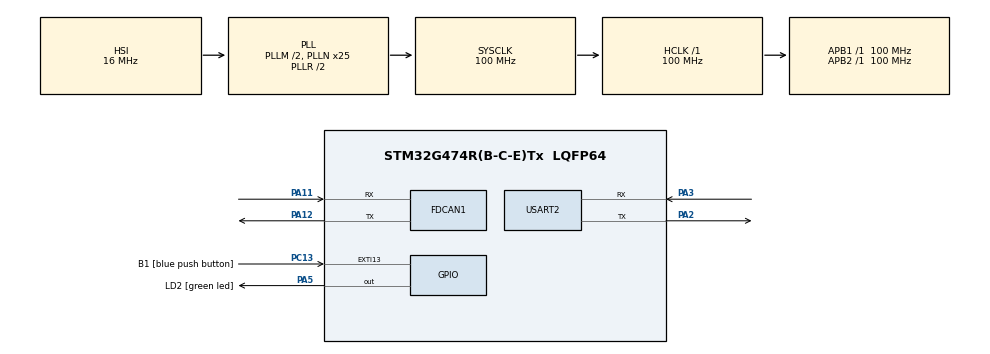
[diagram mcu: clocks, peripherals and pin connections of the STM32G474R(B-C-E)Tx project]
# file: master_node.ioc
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CRC.CRCLength=CRC_POLYLENGTH_16B
CRC.DefaultInitValueUse=DEFAULT_INIT_VALUE_DISABLE
CRC.DefaultPolynomialUse=DEFAULT_POLYNOMIAL_DISABLE
CRC.GeneratingPolynomial=X12+X5+X0
CRC.InitValue=0xFFFF
Dma.Request0=USART2_RX
Dma.Request1=USART2_TX
Dma.USART2_RX.0.Direction=DMA_PERIPH_TO_MEMORY
Dma.USART2_RX.0.EventEnable=DISABLE
Dma.USART2_RX.0.Instance=DMA1_Channel1
Dma.USART2_RX.0.MemDataAlignment=DMA_MDATAALIGN_BYTE
Dma.USART2_RX.0.MemInc=DMA_MINC_ENABLE
Dma.USART2_RX.0.Mode=DMA_NORMAL
Dma.USART2_RX.0.PeriphDataAlignment=DMA_PDATAALIGN_BYTE
Dma.USART2_RX.0.PeriphInc=DMA_PINC_DISABLE
Dma.USART2_RX.0.Polarity=HAL_DMAMUX_REQ_GEN_RISING
Dma.USART2_RX.0.Priority=DMA_PRIORITY_LOW
Dma.USART2_RX.0.RequestNumber=1
Dma.USART2_RX.0.SignalID=NONE
Dma.USART2_RX.0.SyncEnable=DISABLE
Dma.USART2_RX.0.SyncPolarity=HAL_DMAMUX_SYNC_NO_EVENT
Dma.USART2_RX.0.SyncRequestNumber=1
Dma.USART2_RX.0.SyncSignalID=NONE
Dma.USART2_TX.1.Direction=DMA_MEMORY_TO_PERIPH
Dma.USART2_TX.1.EventEnable=DISABLE
Dma.USART2_TX.1.Instance=DMA1_Channel2
Dma.USART2_TX.1.MemDataAlignment=DMA_MDATAALIGN_BYTE
Dma.USART2_TX.1.MemInc=DMA_MINC_ENABLE
Dma.USART2_TX.1.Mode=DMA_NORMAL
Dma.USART2_TX.1.PeriphDataAlignment=DMA_PDATAALIGN_BYTE
Dma.USART2_TX.1.PeriphInc=DMA_PINC_DISABLE
Dma.USART2_TX.1.Polarity=HAL_DMAMUX_REQ_GEN_RISING
Dma.USART2_TX.1.Priority=DMA_PRIORITY_LOW
Dma.USART2_TX.1.RequestNumber=1
Dma.USART2_TX.1.SignalID=NONE
Dma.USART2_TX.1.SyncEnable=DISABLE
Dma.USART2_TX.1.SyncPolarity=HAL_DMAMUX_SYNC_NO_EVENT
Dma.USART2_TX.1.SyncRequestNumber=1
Dma.USART2_TX.1.SyncSignalID=NONE
FDCAN1.CalculateBaudRateNominal=1000000
FDCAN1.CalculateTimeBitNominal=1000
FDCAN1.CalculateTimeQuantumNominal=50.0
FDCAN1.NominalPrescaler=5
FDCAN1.NominalTimeSeg1=13
FDCAN1.NominalTimeSeg2=6
FREERTOS.Tasks01=defaultTask,8,128,defaultTaskFunc,Default,NULL,Dynamic,NULL,NULL
FREERTOS.configTOTAL_HEAP_SIZE=8192
Mcu.Family=STM32G4
Mcu.Name=STM32G474R(B-C-E)Tx
Mcu.Package=LQFP64
NVIC.DMA1_Channel1_IRQn=true\:5\:0\:false\:true\:true\:1\:true\:false\:true\:true
NVIC.DMA1_Channel2_IRQn=true\:5\:0\:false\:false\:true\:true\:false\:true\:true
NVIC.EXTI15_10_IRQn=true\:5\:0\:false\:false\:true\:true\:true\:true\:true
NVIC.FDCAN1_IT0_IRQn=true\:5\:0\:false\:false\:true\:true\:true\:true\:true
NVIC.PriorityGroup=NVIC_PRIORITYGROUP_4
NVIC.TIM6_DAC_IRQn=true\:15\:0\:false\:false\:true\:false\:false\:true\:true
NVIC.TimeBase=TIM6_DAC_IRQn
NVIC.TimeBaseIP=TIM6
NVIC.USART2_IRQn=true\:5\:0\:false\:true\:true\:2\:true\:true\:true\:true
PA11.Mode=FDCAN_Activate
PA11.Signal=FDCAN1_RX
PA12.Mode=FDCAN_Activate
PA12.Signal=FDCAN1_TX
PA13.GPIO_Label=T_SWDIO
PA13.Signal=SYS_JTMS-SWDIO
PA14.GPIO_Label=T_SWCLK
PA14.Signal=SYS_JTCK-SWCLK
PA2.Mode=Asynchronous
PA2.Signal=USART2_TX
PA3.Mode=Asynchronous
PA3.Signal=USART2_RX
PA5.GPIO_Label=LD2 [green led]
PA5.Signal=GPIO_Output
PB3.GPIO_Label=T_SWO
PB3.Signal=SYS_JTDO-SWO
PC13.GPIO_Label=B1 [blue push button]
PC13.Signal=GPXTI13
PC14-OSC32_IN.GPIO_Label=RCC_OSC32_IN
PC14-OSC32_IN.Signal=RCC_OSC32_IN
PC15-OSC32_OUT.GPIO_Label=RCC_OSC32_OUT
PC15-OSC32_OUT.Signal=RCC_OSC32_OUT
PF0-OSC_IN.GPIO_Label=RCC_OSC_IN
PF0-OSC_IN.Signal=RCC_OSC_IN
PF1-OSC_OUT.GPIO_Label=RCC_OSC_OUT
PF1-OSC_OUT.Signal=RCC_OSC_OUT
ProjectManager.HeapSize=0x200
ProjectManager.StackSize=0x400
ProjectManager.TargetToolchain=CMake
RCC.ADC12Freq_Value=100000000
RCC.ADC345Freq_Value=100000000
RCC.AHBFreq_Value=100000000
RCC.APB1Freq_Value=100000000
RCC.APB1TimFreq_Value=100000000
RCC.APB2Freq_Value=100000000
RCC.APB2TimFreq_Value=100000000
RCC.CortexFreq_Value=100000000
RCC.EXTERNAL_CLOCK_VALUE=12288000
RCC.HCLKFreq_Value=100000000
RCC.HSE_VALUE=24000000
RCC.HSI48_VALUE=48000000
RCC.HSI_VALUE=16000000
RCC.LSE_VALUE=32768
RCC.PLLM=RCC_PLLM_DIV2
RCC.PLLN=25
RCC.RTCClockSelection=RCC_RTCCLKSOURCE_LSE
RCC.SYSCLKFreq_VALUE=100000000
RCC.SYSCLKSource=RCC_SYSCLKSOURCE_PLLCLK
RCC.USBFreq_Value=100000000
RCC.VCOOutputFreq_Value=200000000
USART2.VirtualMode-Asynchronous=VM_ASYNC
VP_CRC_VS_CRC.Mode=CRC_Activate
VP_FREERTOS_VS_CMSIS_V2.Mode=CMSIS_V2
VP_SYS_VS_DBSignals.Mode=DisableDeadBatterySignals
VP_SYS_VS_tim6.Mode=TIM6
board=NUCLEO-G474RE

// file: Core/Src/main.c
/* USER CODE BEGIN Header */
/**
  ******************************************************************************
  * @file           : main.c
  * @brief          : Main program body
  ******************************************************************************
  * @attention
  *
  * Copyright (c) 2025 STMicroelectronics.
  * All rights reserved.
  *
  * This software is licensed under terms that can be found in the LICENSE file
  * in the root directory of this software component.
  * If no LICENSE file comes with this software, it is provided AS-IS.
  *
  ******************************************************************************
  */
/* USER CODE END Header */
#include "main.h"
#include "cmsis_os.h"
#include "crc.h"
#include "dma.h"
#include "fdcan.h"
#include "usart.h"
#include "gpio.h"

/* USER CODE BEGIN Includes */
#include "skm_main/skm_main.h"

/* USER CODE END Includes */

void SystemClock_Config(void);
void MX_FREERTOS_Init(void);
static void MX_NVIC_Init(void);

int main(void)
{

  /* MCU Configuration--------------------------------------------------------*/

  /* Reset of all peripherals, Initializes the Flash interface and the Systick. */
  HAL_Init();

  /* Configure the system clock */
  SystemClock_Config();

  /* Initialize all configured peripherals */
  MX_GPIO_Init();
  MX_DMA_Init();
  MX_FDCAN1_Init();
  MX_USART2_UART_Init();
  MX_CRC_Init();

  /* Initialize interrupts */
  MX_NVIC_Init();
  /* USER CODE BEGIN 2 */
  init();

  /* USER CODE END 2 */

  /* Init scheduler */
  osKernelInitialize();

  /* Call init function for freertos objects (in cmsis_os2.c) */
  MX_FREERTOS_Init();

  /* Start scheduler */
  osKernelStart();

  /* We should never get here as control is now taken by the scheduler */

  /* Infinite loop */
  while (1)
  {

  }
}

void SystemClock_Config(void)
{
  RCC_OscInitTypeDef RCC_OscInitStruct = {0};
  RCC_ClkInitTypeDef RCC_ClkInitStruct = {0};

  /** Configure the main internal regulator output voltage
  */
  HAL_PWREx_ControlVoltageScaling(PWR_REGULATOR_VOLTAGE_SCALE1);

  /** Initializes the RCC Oscillators according to the specified parameters
  * in the RCC_OscInitTypeDef structure.
  */
  RCC_OscInitStruct.OscillatorType = RCC_OSCILLATORTYPE_HSI;
  RCC_OscInitStruct.HSIState = RCC_HSI_ON;
  RCC_OscInitStruct.HSICalibrationValue = RCC_HSICALIBRATION_DEFAULT;
  RCC_OscInitStruct.PLL.PLLState = RCC_PLL_ON;
  RCC_OscInitStruct.PLL.PLLSource = RCC_PLLSOURCE_HSI;
  RCC_OscInitStruct.PLL.PLLM = RCC_PLLM_DIV2;
  RCC_OscInitStruct.PLL.PLLN = 25;
  RCC_OscInitStruct.PLL.PLLP = RCC_PLLP_DIV2;
  RCC_OscInitStruct.PLL.PLLQ = RCC_PLLQ_DIV2;
  RCC_OscInitStruct.PLL.PLLR = RCC_PLLR_DIV2;
  if (HAL_RCC_OscConfig(&RCC_OscInitStruct) != HAL_OK)
  {
    Error_Handler();
  }

  /** Initializes the CPU, AHB and APB buses clocks
  */
  RCC_ClkInitStruct.ClockType = RCC_CLOCKTYPE_HCLK|RCC_CLOCKTYPE_SYSCLK
                              |RCC_CLOCKTYPE_PCLK1|RCC_CLOCKTYPE_PCLK2;
  RCC_ClkInitStruct.SYSCLKSource = RCC_SYSCLKSOURCE_PLLCLK;
  RCC_ClkInitStruct.AHBCLKDivider = RCC_SYSCLK_DIV1;
  RCC_ClkInitStruct.APB1CLKDivider = RCC_HCLK_DIV1;
  RCC_ClkInitStruct.APB2CLKDivider = RCC_HCLK_DIV1;

  if (HAL_RCC_ClockConfig(&RCC_ClkInitStruct, FLASH_LATENCY_3) != HAL_OK)
  {
    Error_Handler();
  }
}

/**
  * @brief NVIC Configuration.
  * @retval None
  */
static void MX_NVIC_Init(void)
{
  /* DMA1_Channel1_IRQn interrupt configuration */
  HAL_NVIC_SetPriority(DMA1_Channel1_IRQn, 5, 0);
  HAL_NVIC_EnableIRQ(DMA1_Channel1_IRQn);
  /* USART2_IRQn interrupt configuration */
  HAL_NVIC_SetPriority(USART2_IRQn, 5, 0);
  HAL_NVIC_EnableIRQ(USART2_IRQn);
}

void HAL_TIM_PeriodElapsedCallback(TIM_HandleTypeDef *htim)
{
  if (htim->Instance == TIM6)
  {
    HAL_IncTick();
  }
}

void Error_Handler(void)
{
  /* USER CODE BEGIN Error_Handler_Debug */
  /* User can add his own implementation to report the HAL error return state */
  error_handler();
  __disable_irq();
  while (1)
  {
  }
  /* USER CODE END Error_Handler_Debug */
}

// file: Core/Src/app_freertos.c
/* USER CODE BEGIN Header */
/**
  ******************************************************************************
  * File Name          : app_freertos.c
  * Description        : Code for freertos applications
  ******************************************************************************
  * @attention
  *
  * Copyright (c) 2025 STMicroelectronics.
  * All rights reserved.
  *
  * This software is licensed under terms that can be found in the LICENSE file
  * in the root directory of this software component.
  * If no LICENSE file comes with this software, it is provided AS-IS.
  *
  ******************************************************************************
  */
/* USER CODE END Header */

#include "FreeRTOS.h"
#include "task.h"
#include "main.h"
#include "cmsis_os.h"

/* USER CODE BEGIN Includes */
#include "fdcan.h"

/* USER CODE END Includes */

/* Definitions for defaultTask */
osThreadId_t defaultTaskHandle;
const osThreadAttr_t defaultTask_attributes = {
  .name = "defaultTask",
  .priority = (osPriority_t) osPriorityLow,
  .stack_size = 128 * 4
};

void defaultTaskFunc(void *argument);

void MX_FREERTOS_Init(void); /* (MISRA C 2004 rule 8.1) */

void MX_FREERTOS_Init(void) {

  /* Create the thread(s) */
  /* creation of defaultTask */
  defaultTaskHandle = osThreadNew(defaultTaskFunc, NULL, &defaultTask_attributes);

}

void defaultTaskFunc(void *argument)
{
  /* USER CODE BEGIN defaultTaskFunc */
  /* Infinite loop */
  for(;;)
  {
    HAL_GPIO_TogglePin(LD2_GPIO_Port, LD2_Pin);
    osDelay(1000);
  }
  /* USER CODE END defaultTaskFunc */
}
